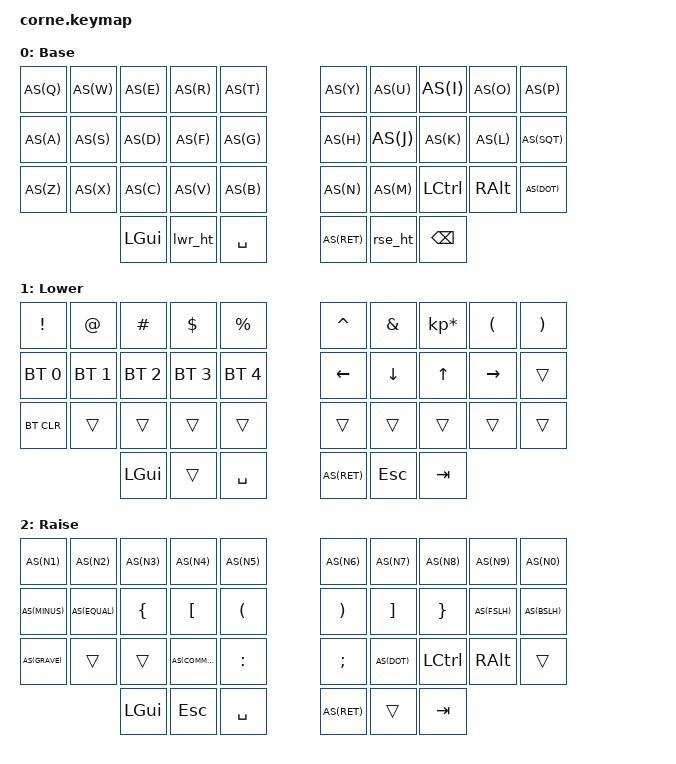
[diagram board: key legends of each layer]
/*
 * Copyright (c) 2020 The ZMK Contributors
 * SPDX-License-Identifier: MIT
 */

#include <behaviors.dtsi>
#include <dt-bindings/zmk/keys.h>
#include <dt-bindings/zmk/bt.h>

#define AS(keycode) &as LS(keycode) keycode

/ {
    chosen {
        zmk,physical-layout = &foostan_corne_5col_layout;
    };

    behaviors {
        as: auto_shift {
            compatible = "zmk,behavior-hold-tap";
            #binding-cells = <2>;
            tapping-term-ms = <200>;
            quick-tap-ms = <0>;
            flavor = "tap-preferred";
            bindings = <&kp>, <&kp>;
        };

        sticky_lower: sticky_lower {
            compatible = "zmk,behavior-sticky-key";
            label = "Sticky Lower";
            #binding-cells = <1>;
            bindings = <&mo 1>;
        };

        sticky_raise: sticky_raise {
            compatible = "zmk,behavior-sticky-key";
            label = "Sticky Raise";
            #binding-cells = <1>;
            bindings = <&mo 2>;
        };

        lwr_ht: lwr_ht {
            compatible = "zmk,behavior-hold-tap";
            #binding-cells = <0>;
            tapping-term-ms = <200>;
            flavor = "hold-preferred";
            bindings = <&mo 1>, <&kp LCTL>;
        };

        rse_ht: rse_ht {
            compatible = "zmk,behavior-hold-tap";
            #binding-cells = <0>;
            tapping-term-ms = <200>;
            flavor = "hold-preferred";
            bindings = <&mo 2>, <&kp RALT>;
        };
    };

    keymap {
        compatible = "zmk,keymap";

        default_layer {
            display-name = "Base";
            bindings = <
                AS(Q)   AS(W)   AS(E)   AS(R)   AS(T)       AS(Y)   AS(U)   AS(I)     AS(O)     AS(P)
                AS(A)   AS(S)   AS(D)   AS(F)   AS(G)       AS(H)   AS(J)   AS(K)     AS(L)     AS(SQT)
                AS(Z)   AS(X)   AS(C)   AS(V)   AS(B)       AS(N)   AS(M)   &kp LCTL  &kp RALT  AS(DOT)
                        &kp LGUI  &lwr_ht &kp SPACE        AS(RET)  &rse_ht &kp BSPC
            >;
        };

        lower_layer {
            display-name = "Lower";
            bindings = <
                &kp EXCL     &kp AT       &kp HASH     &kp DLLR     &kp PRCNT     &kp CARET  &kp AMPS  &kp KP_MULTIPLY &kp LPAR   &kp RPAR
                &bt BT_SEL 0 &bt BT_SEL 1 &bt BT_SEL 2 &bt BT_SEL 3 &bt BT_SEL 4  &kp LEFT   &kp DOWN  &kp UP          &kp RIGHT  &trans
                &bt BT_CLR   &trans       &trans       &trans       &trans        &trans     &trans    &trans          &trans     &trans
                                &kp LGUI   &trans       &kp SPACE    AS(RET)       &kp ESC    &kp TAB
            >;
        };

        raise_layer {
            display-name = "Raise";
            bindings = <
                AS(N1)    AS(N2)    AS(N3)    AS(N4)    AS(N5)       AS(N6)    AS(N7)    AS(N8)    AS(N9)   AS(N0)
                AS(MINUS) AS(EQUAL) &kp LBRC  &kp LBKT  &kp LPAR     &kp RPAR  &kp RBKT  &kp RBRC  AS(FSLH) AS(BSLH)
                AS(GRAVE) &trans    &trans    AS(COMMA) &kp COLON    &kp SEMI  AS(DOT)   &kp LCTRL &kp RALT &trans
                            &kp LGUI  &kp ESC  &kp SPACE  AS(RET)    &trans    &kp TAB
            >;
        };

        extra_1 { status = "reserved"; };
        extra_2 { status = "reserved"; };
        extra_3 { status = "reserved"; };
    };

    combos {
        compatible = "zmk,combos";

        double_tap_lwr {
            timeout-ms = <200>;
            key-positions = <31 31>; // lwr_ht index (assumed correct)
            bindings = <&sticky_lower 1>;
        };

        double_tap_rse {
            timeout-ms = <200>;
            key-positions = <34 34>; // rse_ht index (assumed correct)
            bindings = <&sticky_raise 2>;
        };
    };
};
